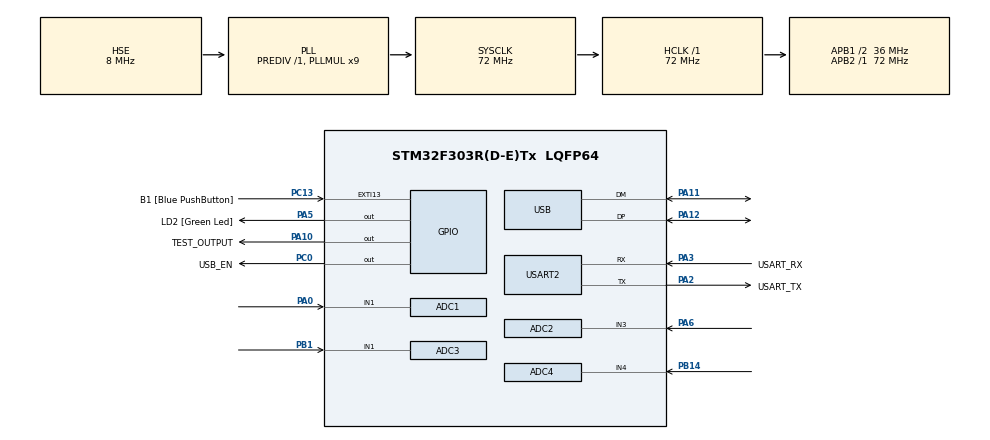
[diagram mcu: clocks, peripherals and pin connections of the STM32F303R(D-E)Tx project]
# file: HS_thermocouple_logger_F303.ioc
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ADC1.Channel-1\#ChannelRegularConversion=ADC_CHANNEL_1
ADC1.ClockPrescaler=ADC_CLOCK_SYNC_PCLK_DIV1
ADC1.ContinuousConvMode=ENABLE
ADC1.EOCSelection=ADC_EOC_SINGLE_CONV
ADC1.NbrOfConversionFlag=1
ADC1.Offset-1\#ChannelRegularConversion=0
ADC1.OffsetNumber-1\#ChannelRegularConversion=ADC_OFFSET_NONE
ADC1.Rank-1\#ChannelRegularConversion=1
ADC1.SamplingTime-1\#ChannelRegularConversion=ADC_SAMPLETIME_1CYCLE_5
ADC1.master=1
ADC2.Channel-0\#ChannelRegularConversion=ADC_CHANNEL_3
ADC2.ClockPrescaler=ADC_CLOCK_SYNC_PCLK_DIV1
ADC2.NbrOfConversionFlag=1
ADC2.Offset-0\#ChannelRegularConversion=0
ADC2.OffsetNumber-0\#ChannelRegularConversion=ADC_OFFSET_NONE
ADC2.Rank-0\#ChannelRegularConversion=1
ADC2.SamplingTime-0\#ChannelRegularConversion=ADC_SAMPLETIME_1CYCLE_5
ADC3.Channel-0\#ChannelRegularConversion=ADC_CHANNEL_1
ADC3.ClockPrescaler=ADC_CLOCK_SYNC_PCLK_DIV2
ADC3.NbrOfConversionFlag=1
ADC3.Offset-0\#ChannelRegularConversion=0
ADC3.OffsetNumber-0\#ChannelRegularConversion=ADC_OFFSET_NONE
ADC3.Rank-0\#ChannelRegularConversion=1
ADC3.SamplingTime-0\#ChannelRegularConversion=ADC_SAMPLETIME_1CYCLE_5
ADC3.master=1
ADC4.Channel-0\#ChannelRegularConversion=ADC_CHANNEL_4
ADC4.ClockPrescaler=ADC_CLOCK_SYNC_PCLK_DIV2
ADC4.NbrOfConversionFlag=1
ADC4.Offset-0\#ChannelRegularConversion=0
ADC4.OffsetNumber-0\#ChannelRegularConversion=ADC_OFFSET_NONE
ADC4.Rank-0\#ChannelRegularConversion=1
ADC4.SamplingTime-0\#ChannelRegularConversion=ADC_SAMPLETIME_1CYCLE_5
ADC4.SamplingTimeOPAMP-0\#ChannelRegularConversion=ADC_SAMPLETIME_61CYCLES_5
Dma.ADC1.0.Direction=DMA_PERIPH_TO_MEMORY
Dma.ADC1.0.Instance=DMA1_Channel1
Dma.ADC1.0.MemDataAlignment=DMA_MDATAALIGN_HALFWORD
Dma.ADC1.0.MemInc=DMA_MINC_ENABLE
Dma.ADC1.0.Mode=DMA_NORMAL
Dma.ADC1.0.PeriphDataAlignment=DMA_PDATAALIGN_HALFWORD
Dma.ADC1.0.PeriphInc=DMA_PINC_DISABLE
Dma.ADC1.0.Priority=DMA_PRIORITY_LOW
Dma.ADC2.1.Direction=DMA_PERIPH_TO_MEMORY
Dma.ADC2.1.Instance=DMA2_Channel1
Dma.ADC2.1.MemDataAlignment=DMA_MDATAALIGN_HALFWORD
Dma.ADC2.1.MemInc=DMA_MINC_ENABLE
Dma.ADC2.1.Mode=DMA_NORMAL
Dma.ADC2.1.PeriphDataAlignment=DMA_PDATAALIGN_HALFWORD
Dma.ADC2.1.PeriphInc=DMA_PINC_DISABLE
Dma.ADC2.1.Priority=DMA_PRIORITY_LOW
Dma.ADC3.2.Direction=DMA_PERIPH_TO_MEMORY
Dma.ADC3.2.Instance=DMA2_Channel5
Dma.ADC3.2.MemDataAlignment=DMA_MDATAALIGN_HALFWORD
Dma.ADC3.2.MemInc=DMA_MINC_ENABLE
Dma.ADC3.2.Mode=DMA_NORMAL
Dma.ADC3.2.PeriphDataAlignment=DMA_PDATAALIGN_HALFWORD
Dma.ADC3.2.PeriphInc=DMA_PINC_DISABLE
Dma.ADC3.2.Priority=DMA_PRIORITY_LOW
Dma.ADC4.3.Direction=DMA_PERIPH_TO_MEMORY
Dma.ADC4.3.Instance=DMA2_Channel2
Dma.ADC4.3.MemDataAlignment=DMA_MDATAALIGN_HALFWORD
Dma.ADC4.3.MemInc=DMA_MINC_ENABLE
Dma.ADC4.3.Mode=DMA_NORMAL
Dma.ADC4.3.PeriphDataAlignment=DMA_PDATAALIGN_HALFWORD
Dma.ADC4.3.PeriphInc=DMA_PINC_DISABLE
Dma.ADC4.3.Priority=DMA_PRIORITY_LOW
Dma.Request0=ADC1
Dma.Request1=ADC2
Dma.Request2=ADC3
Dma.Request3=ADC4
Mcu.Family=STM32F3
Mcu.Name=STM32F303R(D-E)Tx
Mcu.Package=LQFP64
NVIC.DMA1_Channel1_IRQn=true\:0\:0\:false\:false\:true\:false\:true\:true
NVIC.DMA2_Channel1_IRQn=true\:0\:0\:false\:false\:true\:false\:true\:true
NVIC.DMA2_Channel2_IRQn=true\:0\:0\:false\:false\:true\:false\:true\:true
NVIC.DMA2_Channel5_IRQn=true\:0\:0\:false\:false\:true\:false\:true\:true
NVIC.PriorityGroup=NVIC_PRIORITYGROUP_0
NVIC.TIM2_IRQn=true\:0\:0\:false\:false\:true\:true\:true\:true
NVIC.USB_HP_CAN_TX_IRQn=true\:0\:0\:false\:false\:true\:true\:true\:true
NVIC.USB_LP_CAN_RX0_IRQn=true\:0\:0\:false\:false\:true\:true\:true\:true
PA0.Mode=IN1-Single-Ended
PA0.Signal=ADC1_IN1
PA10.GPIO_Label=TEST_OUTPUT
PA10.GPIO_Speed=GPIO_SPEED_FREQ_HIGH
PA10.Signal=GPIO_Output
PA11.Mode=Device
PA11.Signal=USB_DM
PA12.Mode=Device
PA12.Signal=USB_DP
PA13.GPIO_Label=TMS
PA13.Mode=Serial_Wire
PA13.Signal=SYS_JTMS-SWDIO
PA14.GPIO_Label=TCK
PA14.Mode=Serial_Wire
PA14.Signal=SYS_JTCK-SWCLK
PA2.GPIO_Label=USART_TX
PA2.GPIO_Mode=GPIO_MODE_AF_PP
PA2.GPIO_PuPd=GPIO_NOPULL
PA2.GPIO_Speed=GPIO_SPEED_FREQ_LOW
PA2.Mode=Asynchronous
PA2.Signal=USART2_TX
PA3.GPIO_Label=USART_RX
PA3.GPIO_Mode=GPIO_MODE_AF_PP
PA3.GPIO_PuPd=GPIO_NOPULL
PA3.GPIO_Speed=GPIO_SPEED_FREQ_LOW
PA3.Mode=Asynchronous
PA3.Signal=USART2_RX
PA5.GPIO_Label=LD2 [Green Led]
PA5.GPIO_Mode=GPIO_MODE_OUTPUT_PP
PA5.GPIO_PuPd=GPIO_NOPULL
PA5.GPIO_Speed=GPIO_SPEED_FREQ_LOW
PA5.Signal=GPIO_Output
PA6.Mode=IN3-Single-Ended
PA6.Signal=ADC2_IN3
PB1.Mode=IN1-Single-Ended
PB1.Signal=ADC3_IN1
PB14.Mode=IN4-Single-Ended
PB14.Signal=ADC4_IN4
PB3.Signal=SYS_JTDO-TRACESWO
PC0.GPIO_Label=USB_EN
PC0.PinState=GPIO_PIN_RESET
PC0.Signal=GPIO_Output
PC13.GPIO_Label=B1 [Blue PushButton]
PC13.GPIO_ModeDefaultEXTI=GPIO_MODE_IT_FALLING
PC13.Signal=GPXTI13
PC14-OSC32_IN.Signal=RCC_OSC32_IN
PC15-OSC32_OUT.Signal=RCC_OSC32_OUT
PF0-OSC_IN.Mode=HSE-External-Oscillator
PF0-OSC_IN.Signal=RCC_OSC_IN
PF1-OSC_OUT.Mode=HSE-External-Oscillator
PF1-OSC_OUT.Signal=RCC_OSC_OUT
ProjectManager.HeapSize=0x1000
ProjectManager.StackSize=0x8000
ProjectManager.TargetToolchain=STM32CubeIDE
RCC.AHBFreq_Value=72000000
RCC.APB1CLKDivider=RCC_HCLK_DIV2
RCC.APB1Freq_Value=36000000
RCC.APB1TimFreq_Value=72000000
RCC.APB2Freq_Value=72000000
RCC.APB2TimFreq_Value=72000000
RCC.CortexFreq_Value=72000000
RCC.HCLKFreq_Value=72000000
RCC.HSE_VALUE=8000000
RCC.HSI_VALUE=8000000
RCC.LSE_VALUE=32768
RCC.PLLM=8
RCC.PLLMUL=RCC_PLL_MUL9
RCC.PLLN=336
RCC.PLLP=RCC_PLLP_DIV4
RCC.PLLQ=7
RCC.PRESCALERUSB=RCC_USBCLKSOURCE_PLL_DIV1_5
RCC.RCC_PLLsource_Clock_Source_FROM_HSE=RCC_HSE_PREDIV_DIV2
RCC.SYSCLKFreq_VALUE=72000000
RCC.SYSCLKSourceVirtual=RCC_SYSCLKSOURCE_PLLCLK
RCC.USBFreq_Value=48000000
TIM2.Period=1000 - 1
TIM2.Prescaler=72 - 1
USART2.VirtualMode-Asynchronous=VM_ASYNC
USB_DEVICE.CLASS_NAME_FS=CDC
USB_DEVICE.USBD_SELF_POWERED=1
USB_DEVICE.VirtualMode=Cdc
USB_DEVICE.VirtualModeFS=Cdc_FS
VP_TIM2_VS_ClockSourceINT.Mode=Internal
VP_USB_DEVICE_VS_USB_DEVICE_CDC_FS.Mode=CDC_FS
board=NUCLEO-F303RE

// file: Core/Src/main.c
/* USER CODE BEGIN Header */
/**
  ******************************************************************************
  * @file           : main.c
  * @brief          : Main program body
  ******************************************************************************
  * @attention
  *
  * Copyright (c) 2024 STMicroelectronics.
  * All rights reserved.
  *
  * This software is licensed under terms that can be found in the LICENSE file
  * in the root directory of this software component.
  * If no LICENSE file comes with this software, it is provided AS-IS.
  *
  ******************************************************************************
  */
/* USER CODE END Header */
#include "main.h"
#include "usb_device.h"

/* USER CODE BEGIN Includes */
#include "usbd_cdc_if.h"
/* USER CODE END Includes */

/* USER CODE BEGIN PD */
#define USB_BUFFER_SIZE 4095
/* USER CODE END PD */

ADC_HandleTypeDef hadc1;
ADC_HandleTypeDef hadc2;
ADC_HandleTypeDef hadc3;
ADC_HandleTypeDef hadc4;
DMA_HandleTypeDef hdma_adc1;
DMA_HandleTypeDef hdma_adc2;
DMA_HandleTypeDef hdma_adc3;
DMA_HandleTypeDef hdma_adc4;

TIM_HandleTypeDef htim2;

UART_HandleTypeDef huart2;

/* USER CODE BEGIN PV */
int current_tick;
/* USER CODE END PV */

void SystemClock_Config(void);
static void MX_GPIO_Init(void);
static void MX_DMA_Init(void);
static void MX_USART2_UART_Init(void);
static void MX_ADC1_Init(void);
static void MX_ADC2_Init(void);
static void MX_ADC3_Init(void);
static void MX_ADC4_Init(void);
static void MX_TIM2_Init(void);

int main(void)
{

  /* MCU Configuration--------------------------------------------------------*/

  /* Reset of all peripherals, Initializes the Flash interface and the Systick. */
  HAL_Init();

  /* Configure the system clock */
  SystemClock_Config();

  /* Initialize all configured peripherals */
  MX_GPIO_Init();
  MX_DMA_Init();
  MX_USART2_UART_Init();
  MX_ADC1_Init();
  MX_ADC2_Init();
  MX_ADC3_Init();
  MX_ADC4_Init();
  MX_TIM2_Init();
  MX_USB_DEVICE_Init();
  /* USER CODE BEGIN 2 */
//  HAL_TIM_Base_Start_IT(&htim2);

  /* USER CODE END 2 */

  /* Infinite loop */
  /* USER CODE BEGIN WHILE */

  uint8_t bufferA[USB_BUFFER_SIZE];
  uint8_t bufferB[USB_BUFFER_SIZE];
  for(int i = 0; i<USB_BUFFER_SIZE; i++){
      bufferA[i] = i%256;
      bufferB[i] = i%256;
  }
  HAL_Delay(1000);
  while (1)
  {
    /* USER CODE END WHILE */

    /* USER CODE BEGIN 3 */
      CDC_Transmit_FS(bufferA, USB_BUFFER_SIZE);

      CDC_Transmit_FS(bufferB, USB_BUFFER_SIZE);

  }
  /* USER CODE END 3 */
}

void SystemClock_Config(void)
{
  RCC_OscInitTypeDef RCC_OscInitStruct = {0};
  RCC_ClkInitTypeDef RCC_ClkInitStruct = {0};
  RCC_PeriphCLKInitTypeDef PeriphClkInit = {0};

  /** Initializes the RCC Oscillators according to the specified parameters
  * in the RCC_OscInitTypeDef structure.
  */
  RCC_OscInitStruct.OscillatorType = RCC_OSCILLATORTYPE_HSE;
  RCC_OscInitStruct.HSEState = RCC_HSE_ON;
  RCC_OscInitStruct.HSIState = RCC_HSI_ON;
  RCC_OscInitStruct.PLL.PLLState = RCC_PLL_ON;
  RCC_OscInitStruct.PLL.PLLSource = RCC_PLLSOURCE_HSE;
  RCC_OscInitStruct.PLL.PLLMUL = RCC_PLL_MUL9;
  RCC_OscInitStruct.PLL.PREDIV = RCC_PREDIV_DIV1;
  if (HAL_RCC_OscConfig(&RCC_OscInitStruct) != HAL_OK)
  {
    Error_Handler();
  }

  /** Initializes the CPU, AHB and APB buses clocks
  */
  RCC_ClkInitStruct.ClockType = RCC_CLOCKTYPE_HCLK|RCC_CLOCKTYPE_SYSCLK
                              |RCC_CLOCKTYPE_PCLK1|RCC_CLOCKTYPE_PCLK2;
  RCC_ClkInitStruct.SYSCLKSource = RCC_SYSCLKSOURCE_PLLCLK;
  RCC_ClkInitStruct.AHBCLKDivider = RCC_SYSCLK_DIV1;
  RCC_ClkInitStruct.APB1CLKDivider = RCC_HCLK_DIV2;
  RCC_ClkInitStruct.APB2CLKDivider = RCC_HCLK_DIV1;

  if (HAL_RCC_ClockConfig(&RCC_ClkInitStruct, FLASH_LATENCY_2) != HAL_OK)
  {
    Error_Handler();
  }
  PeriphClkInit.PeriphClockSelection = RCC_PERIPHCLK_USB|RCC_PERIPHCLK_USART2
                              |RCC_PERIPHCLK_TIM2;
  PeriphClkInit.Usart2ClockSelection = RCC_USART2CLKSOURCE_PCLK1;
  PeriphClkInit.USBClockSelection = RCC_USBCLKSOURCE_PLL_DIV1_5;
  PeriphClkInit.Tim2ClockSelection = RCC_TIM2CLK_HCLK;
  if (HAL_RCCEx_PeriphCLKConfig(&PeriphClkInit) != HAL_OK)
  {
    Error_Handler();
  }
}

static void MX_ADC1_Init(void)
{

  ADC_MultiModeTypeDef multimode = {0};
  ADC_ChannelConfTypeDef sConfig = {0};

  /** Common config
  */
  hadc1.Instance = ADC1;
  hadc1.Init.ClockPrescaler = ADC_CLOCK_SYNC_PCLK_DIV1;
  hadc1.Init.Resolution = ADC_RESOLUTION_12B;
  hadc1.Init.ScanConvMode = ADC_SCAN_DISABLE;
  hadc1.Init.ContinuousConvMode = ENABLE;
  hadc1.Init.DiscontinuousConvMode = DISABLE;
  hadc1.Init.ExternalTrigConvEdge = ADC_EXTERNALTRIGCONVEDGE_NONE;
  hadc1.Init.ExternalTrigConv = ADC_SOFTWARE_START;
  hadc1.Init.DataAlign = ADC_DATAALIGN_RIGHT;
  hadc1.Init.NbrOfConversion = 1;
  hadc1.Init.DMAContinuousRequests = DISABLE;
  hadc1.Init.EOCSelection = ADC_EOC_SINGLE_CONV;
  hadc1.Init.LowPowerAutoWait = DISABLE;
  hadc1.Init.Overrun = ADC_OVR_DATA_OVERWRITTEN;
  if (HAL_ADC_Init(&hadc1) != HAL_OK)
  {
    Error_Handler();
  }

  /** Configure the ADC multi-mode
  */
  multimode.Mode = ADC_MODE_INDEPENDENT;
  if (HAL_ADCEx_MultiModeConfigChannel(&hadc1, &multimode) != HAL_OK)
  {
    Error_Handler();
  }

  /** Configure Regular Channel
  */
  sConfig.Channel = ADC_CHANNEL_1;
  sConfig.Rank = ADC_REGULAR_RANK_1;
  sConfig.SingleDiff = ADC_SINGLE_ENDED;
  sConfig.SamplingTime = ADC_SAMPLETIME_1CYCLE_5;
  sConfig.OffsetNumber = ADC_OFFSET_NONE;
  sConfig.Offset = 0;
  if (HAL_ADC_ConfigChannel(&hadc1, &sConfig) != HAL_OK)
  {
    Error_Handler();
  }

}

static void MX_ADC2_Init(void)
{

  ADC_ChannelConfTypeDef sConfig = {0};

  /** Common config
  */
  hadc2.Instance = ADC2;
  hadc2.Init.ClockPrescaler = ADC_CLOCK_SYNC_PCLK_DIV1;
  hadc2.Init.Resolution = ADC_RESOLUTION_12B;
  hadc2.Init.ScanConvMode = ADC_SCAN_DISABLE;
  hadc2.Init.ContinuousConvMode = DISABLE;
  hadc2.Init.DiscontinuousConvMode = DISABLE;
  hadc2.Init.ExternalTrigConvEdge = ADC_EXTERNALTRIGCONVEDGE_NONE;
  hadc2.Init.ExternalTrigConv = ADC_SOFTWARE_START;
  hadc2.Init.DataAlign = ADC_DATAALIGN_RIGHT;
  hadc2.Init.NbrOfConversion = 1;
  hadc2.Init.DMAContinuousRequests = DISABLE;
  hadc2.Init.EOCSelection = ADC_EOC_SINGLE_CONV;
  hadc2.Init.LowPowerAutoWait = DISABLE;
  hadc2.Init.Overrun = ADC_OVR_DATA_OVERWRITTEN;
  if (HAL_ADC_Init(&hadc2) != HAL_OK)
  {
    Error_Handler();
  }

  /** Configure Regular Channel
  */
  sConfig.Channel = ADC_CHANNEL_3;
  sConfig.Rank = ADC_REGULAR_RANK_1;
  sConfig.SingleDiff = ADC_SINGLE_ENDED;
  sConfig.SamplingTime = ADC_SAMPLETIME_1CYCLE_5;
  sConfig.OffsetNumber = ADC_OFFSET_NONE;
  sConfig.Offset = 0;
  if (HAL_ADC_ConfigChannel(&hadc2, &sConfig) != HAL_OK)
  {
    Error_Handler();
  }

}

static void MX_ADC3_Init(void)
{

  ADC_MultiModeTypeDef multimode = {0};
  ADC_ChannelConfTypeDef sConfig = {0};

  /** Common config
  */
  hadc3.Instance = ADC3;
  hadc3.Init.ClockPrescaler = ADC_CLOCK_SYNC_PCLK_DIV2;
  hadc3.Init.Resolution = ADC_RESOLUTION_12B;
  hadc3.Init.ScanConvMode = ADC_SCAN_DISABLE;
  hadc3.Init.ContinuousConvMode = DISABLE;
  hadc3.Init.DiscontinuousConvMode = DISABLE;
  hadc3.Init.ExternalTrigConvEdge = ADC_EXTERNALTRIGCONVEDGE_NONE;
  hadc3.Init.ExternalTrigConv = ADC_SOFTWARE_START;
  hadc3.Init.DataAlign = ADC_DATAALIGN_RIGHT;
  hadc3.Init.NbrOfConversion = 1;
  hadc3.Init.DMAContinuousRequests = DISABLE;
  hadc3.Init.EOCSelection = ADC_EOC_SINGLE_CONV;
  hadc3.Init.LowPowerAutoWait = DISABLE;
  hadc3.Init.Overrun = ADC_OVR_DATA_OVERWRITTEN;
  if (HAL_ADC_Init(&hadc3) != HAL_OK)
  {
    Error_Handler();
  }

  /** Configure the ADC multi-mode
  */
  multimode.Mode = ADC_MODE_INDEPENDENT;
  if (HAL_ADCEx_MultiModeConfigChannel(&hadc3, &multimode) != HAL_OK)
  {
    Error_Handler();
  }

  /** Configure Regular Channel
  */
  sConfig.Channel = ADC_CHANNEL_1;
  sConfig.Rank = ADC_REGULAR_RANK_1;
  sConfig.SingleDiff = ADC_SINGLE_ENDED;
  sConfig.SamplingTime = ADC_SAMPLETIME_1CYCLE_5;
  sConfig.OffsetNumber = ADC_OFFSET_NONE;
  sConfig.Offset = 0;
  if (HAL_ADC_ConfigChannel(&hadc3, &sConfig) != HAL_OK)
  {
    Error_Handler();
  }

}

static void MX_ADC4_Init(void)
{

  ADC_ChannelConfTypeDef sConfig = {0};

  /** Common config
  */
  hadc4.Instance = ADC4;
  hadc4.Init.ClockPrescaler = ADC_CLOCK_SYNC_PCLK_DIV2;
  hadc4.Init.Resolution = ADC_RESOLUTION_12B;
  hadc4.Init.ScanConvMode = ADC_SCAN_DISABLE;
  hadc4.Init.ContinuousConvMode = DISABLE;
  hadc4.Init.DiscontinuousConvMode = DISABLE;
  hadc4.Init.ExternalTrigConvEdge = ADC_EXTERNALTRIGCONVEDGE_NONE;
  hadc4.Init.ExternalTrigConv = ADC_SOFTWARE_START;
  hadc4.Init.DataAlign = ADC_DATAALIGN_RIGHT;
  hadc4.Init.NbrOfConversion = 1;
  hadc4.Init.DMAContinuousRequests = DISABLE;
  hadc4.Init.EOCSelection = ADC_EOC_SINGLE_CONV;
  hadc4.Init.LowPowerAutoWait = DISABLE;
  hadc4.Init.Overrun = ADC_OVR_DATA_OVERWRITTEN;
  if (HAL_ADC_Init(&hadc4) != HAL_OK)
  {
    Error_Handler();
  }

  /** Configure Regular Channel
  */
  sConfig.Channel = ADC_CHANNEL_4;
  sConfig.Rank = ADC_REGULAR_RANK_1;
  sConfig.SingleDiff = ADC_SINGLE_ENDED;
  sConfig.SamplingTime = ADC_SAMPLETIME_1CYCLE_5;
  sConfig.OffsetNumber = ADC_OFFSET_NONE;
  sConfig.Offset = 0;
  if (HAL_ADC_ConfigChannel(&hadc4, &sConfig) != HAL_OK)
  {
    Error_Handler();
  }

}

static void MX_TIM2_Init(void)
{

  TIM_ClockConfigTypeDef sClockSourceConfig = {0};
  TIM_MasterConfigTypeDef sMasterConfig = {0};

  htim2.Instance = TIM2;
  htim2.Init.Prescaler = 72 - 1;
  htim2.Init.CounterMode = TIM_COUNTERMODE_UP;
  htim2.Init.Period = 1000 - 1;
  htim2.Init.ClockDivision = TIM_CLOCKDIVISION_DIV1;
  htim2.Init.AutoReloadPreload = TIM_AUTORELOAD_PRELOAD_DISABLE;
  if (HAL_TIM_Base_Init(&htim2) != HAL_OK)
  {
    Error_Handler();
  }
  sClockSourceConfig.ClockSource = TIM_CLOCKSOURCE_INTERNAL;
  if (HAL_TIM_ConfigClockSource(&htim2, &sClockSourceConfig) != HAL_OK)
  {
    Error_Handler();
  }
  sMasterConfig.MasterOutputTrigger = TIM_TRGO_RESET;
  sMasterConfig.MasterSlaveMode = TIM_MASTERSLAVEMODE_DISABLE;
  if (HAL_TIMEx_MasterConfigSynchronization(&htim2, &sMasterConfig) != HAL_OK)
  {
    Error_Handler();
  }

}

static void MX_USART2_UART_Init(void)
{

  huart2.Instance = USART2;
  huart2.Init.BaudRate = 38400;
  huart2.Init.WordLength = UART_WORDLENGTH_8B;
  huart2.Init.StopBits = UART_STOPBITS_1;
  huart2.Init.Parity = UART_PARITY_NONE;
  huart2.Init.Mode = UART_MODE_TX_RX;
  huart2.Init.HwFlowCtl = UART_HWCONTROL_NONE;
  huart2.Init.OverSampling = UART_OVERSAMPLING_16;
  huart2.Init.OneBitSampling = UART_ONE_BIT_SAMPLE_DISABLE;
  huart2.AdvancedInit.AdvFeatureInit = UART_ADVFEATURE_NO_INIT;
  if (HAL_UART_Init(&huart2) != HAL_OK)
  {
    Error_Handler();
  }

}

static void MX_DMA_Init(void)
{

  /* DMA controller clock enable */
  __HAL_RCC_DMA1_CLK_ENABLE();
  __HAL_RCC_DMA2_CLK_ENABLE();

  /* DMA interrupt init */
  /* DMA1_Channel1_IRQn interrupt configuration */
  HAL_NVIC_SetPriority(DMA1_Channel1_IRQn, 0, 0);
  HAL_NVIC_EnableIRQ(DMA1_Channel1_IRQn);
  /* DMA2_Channel1_IRQn interrupt configuration */
  HAL_NVIC_SetPriority(DMA2_Channel1_IRQn, 0, 0);
  HAL_NVIC_EnableIRQ(DMA2_Channel1_IRQn);
  /* DMA2_Channel2_IRQn interrupt configuration */
  HAL_NVIC_SetPriority(DMA2_Channel2_IRQn, 0, 0);
  HAL_NVIC_EnableIRQ(DMA2_Channel2_IRQn);
  /* DMA2_Channel5_IRQn interrupt configuration */
  HAL_NVIC_SetPriority(DMA2_Channel5_IRQn, 0, 0);
  HAL_NVIC_EnableIRQ(DMA2_Channel5_IRQn);

}

static void MX_GPIO_Init(void)
{
  GPIO_InitTypeDef GPIO_InitStruct = {0};

  /* GPIO Ports Clock Enable */
  __HAL_RCC_GPIOC_CLK_ENABLE();
  __HAL_RCC_GPIOF_CLK_ENABLE();
  __HAL_RCC_GPIOA_CLK_ENABLE();
  __HAL_RCC_GPIOB_CLK_ENABLE();

  /*Configure GPIO pin Output Level */
  HAL_GPIO_WritePin(USB_EN_GPIO_Port, USB_EN_Pin, GPIO_PIN_RESET);

  /*Configure GPIO pin Output Level */
  HAL_GPIO_WritePin(GPIOA, LD2_Pin|TEST_OUTPUT_Pin, GPIO_PIN_RESET);

  /*Configure GPIO pin : B1_Pin */
  GPIO_InitStruct.Pin = B1_Pin;
  GPIO_InitStruct.Mode = GPIO_MODE_IT_FALLING;
  GPIO_InitStruct.Pull = GPIO_NOPULL;
  HAL_GPIO_Init(B1_GPIO_Port, &GPIO_InitStruct);

  /*Configure GPIO pin : USB_EN_Pin */
  GPIO_InitStruct.Pin = USB_EN_Pin;
  GPIO_InitStruct.Mode = GPIO_MODE_OUTPUT_PP;
  GPIO_InitStruct.Pull = GPIO_NOPULL;
  GPIO_InitStruct.Speed = GPIO_SPEED_FREQ_LOW;
  HAL_GPIO_Init(USB_EN_GPIO_Port, &GPIO_InitStruct);

  /*Configure GPIO pin : LD2_Pin */
  GPIO_InitStruct.Pin = LD2_Pin;
  GPIO_InitStruct.Mode = GPIO_MODE_OUTPUT_PP;
  GPIO_InitStruct.Pull = GPIO_NOPULL;
  GPIO_InitStruct.Speed = GPIO_SPEED_FREQ_LOW;
  HAL_GPIO_Init(LD2_GPIO_Port, &GPIO_InitStruct);

  /*Configure GPIO pin : TEST_OUTPUT_Pin */
  GPIO_InitStruct.Pin = TEST_OUTPUT_Pin;
  GPIO_InitStruct.Mode = GPIO_MODE_OUTPUT_PP;
  GPIO_InitStruct.Pull = GPIO_NOPULL;
  GPIO_InitStruct.Speed = GPIO_SPEED_FREQ_HIGH;
  HAL_GPIO_Init(TEST_OUTPUT_GPIO_Port, &GPIO_InitStruct);

/* USER CODE BEGIN MX_GPIO_Init_2 */
  HAL_GPIO_WritePin(USB_EN_GPIO_Port, USB_EN_Pin, GPIO_PIN_SET);
/* USER CODE END MX_GPIO_Init_2 */
}

void Error_Handler(void)
{
  __disable_irq();
  while (1)
  {
  }
}
